AUTOSAR XML (schema 00049)
package /Application/DltConfig
  dlt log channel to process mapping DltLogChannelToProcessMapping_PreventRollback_TO_PreventRollback: dlt-log-channel=PreventRollback, process=PreventRollback
package /Application/Executable
  executable PreventRollback: category=APPLICATION_LEVEL, logging-behavior=USES-LOGGING, reporting-behavior=REPORTS-EXECUTION-STATE, version=1.0.0
    root sw component prototype AA: application-type=PreventRollback
package /Application/Manifest
  7 x service instance to port prototype mapping:
    PreventRollback_AA_RPortAccrPedal: port-prototype=AA.RPortAccrPedal, service-instance=EEVP_PreventRollback_Consumer_VCS_AccrPedal
    PreventRollback_AA_RPortBCM_ExteriorSignal: port-prototype=AA.RPortBCM_ExteriorSignal, service-instance=EEVP_PreventRollback_Consumer_BCM_ExteriorSignal
    PreventRollback_AA_RPortBrakePedal: port-prototype=AA.RPortBrakePedal, service-instance=EEVP_PreventRollback_Consumer_VCS_BrakePedal
    PreventRollback_AA_RPortGear: port-prototype=AA.RPortGear, service-instance=EEVP_PreventRollback_Consumer_VCS_Gear
    PreventRollback_AA_RPortMain_PDW_Service: port-prototype=AA.RPortMain_PDW_Service, service-instance=EEVP_PreventRollback_Consumer_Main_PDW_Service
    PreventRollback_AA_RPortSoaVehicleInfo: port-prototype=AA.RPortSoaVehicleInfo, service-instance=EEVP_PreventRollback_Consumer_SoaVehicleInfo
    PreventRollback_AA_RPortSubscriptionManagement: port-prototype=AA.RPortSubscriptionManagement, service-instance=EEVP_PreventRollback_Consumer_SubscriptionManagement
package /Application/Process
  process PreventRollback: executable=PreventRollback, state-dependent-startup-config{function-group-state=[SFG07.On, SFG07.Verify], resource-group=DefaultResourceGroup, startup-config=DefaultStartupConfig}
    process state machine PreventRollback: type=ProcessState
package /Application/SwComponent
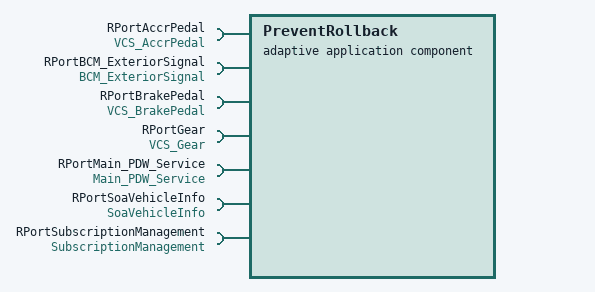
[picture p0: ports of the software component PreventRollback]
  adaptive application sw component type PreventRollback
    7 x require port:
      RPortAccrPedal: required-interface=VCS_AccrPedal
      RPortBCM_ExteriorSignal: required-interface=BCM_ExteriorSignal
      RPortBrakePedal: required-interface=VCS_BrakePedal
      RPortGear: required-interface=VCS_Gear
      RPortMain_PDW_Service: required-interface=Main_PDW_Service
      RPortSoaVehicleInfo: required-interface=SoaVehicleInfo
      RPortSubscriptionManagement: required-interface=SubscriptionManagement
